# AT32F403A register map
Vendor: Keil; Series: AT32F403A; File version: 1.0
CPU: CM4 r0p1, little endian, no MPU, FPU, 4 interrupt priority bits
Registers are 32-bit, read-write, reset 0x0 unless marked. A register's access mark holds for its fields unless they carry their own. Offsets are from the block's base; [hi:lo] are bit positions; {n}, {i} and the like mark numbered series; 'fields as' and 'values as' point back to an identical list.

## RTC — Real time clock
Base 0x40002800
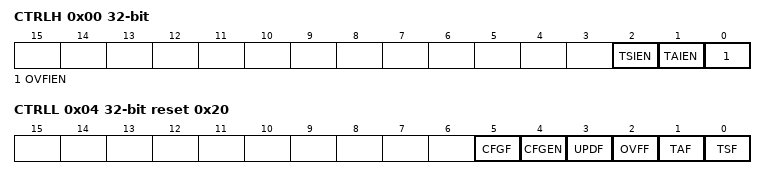
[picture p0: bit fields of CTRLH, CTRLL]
0x00 CTRLH — RTC Control Register High
  [2] TSIEN — Time second interrupt enable
  [1] TAIEN — Time alarm interrupt enable
  [0] OVFIEN — Overflow interrupt enable
0x04 CTRLL reset 0x20 — RTC Control Register Low
  [5] CFGF ro — RTC configuration finish
  [4] CFGEN — RTC configuration enable
  [3] UPDF — RTC update finish
  [2] OVFF — Overflow Flag
  [1] TAF — Time alarm flag
  [0] TSF — Time second flag
0x08 DIVH wo — RTC Divider Register High
  [3:0] DIV — RTC divider high
0x0C DIVL wo reset 0x8000 — RTC Divider Register Low
  [15:0] DIV — RTC divider low
0x10 DIVCNTH — RTC Divider Register High
  [3:0] DIVCNT — RTC divider register high
0x14 DIVCNTL reset 0x8000 — RTC Divider Register Low
  [15:0] DIVCNT — RTC divider register low
0x18 CNTH — RTC Counter Register High
  [15:0] CNT — RTC counter register high
0x1C CNTL — RTC Counter Register Low
  [15:0] CNT — RTC counter register low
0x20 TAH wo reset 0xFFFF — RTC Alarm Register High
  [15:0] TA — Time alarm register high
0x24 TAL wo reset 0xFFFF — Time alarm register low
  [15:0] TA — RTC alarm register low

## BPR — Battery powered register
Base 0x40006C04
0x00 DT{i} (i=1..10; step 0x4) — Battery powered domain data register {i}
  [15:0] DT — BPR data
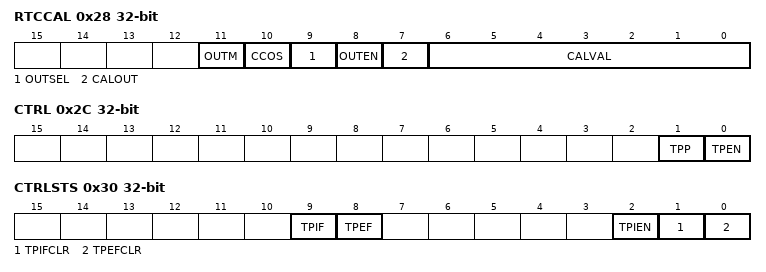
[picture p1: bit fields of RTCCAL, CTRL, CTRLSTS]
0x28 RTCCAL — RTC clock calibration register (BPR_RTCCAL)
  [11] OUTM — Output mode
  [10] CCOS — Calibration clock output selection
  [9] OUTSEL write-1-sets — Output selection
    on read: 0=RTC (RTC alarm event output); 1=Second event output | on write: 1=Second event output
  [8] OUTEN write-1-sets — Output enable
    on read: 0=Disabled (Output is disabled); 1=Enabled (Output is enabled) | on write: 1=Enable (Output enable)
  [7] CALOUT write-1-sets — Calibration Clock Output
    on read: 0=NoOutput (No effect); 1=Output the RTC clock with a frequency divided by 64 on the TAMPER pin | on write: 1=Output the RTC clock with a frequency divided by 64 on the TAMPER pin
  [6:0] CALVAL — Calibration value
0x2C CTRL — BPR control register (BPR_CTRL)
  [1] TPP — TAMPER pin polarity
    0=High (Active high); 1=Low (Active low)
  [0] TPEN — Tamper pin enable
    on read: 0=Disabled (TAMPER pin is disabled); 1=Enabled (TAMPER pin is enabled) | on write: 0=Disable (TAMPER pin disable); 1=Enable (TAMPER pin enable)
0x30 CTRLSTS — BPR control/status register (BPR_CTRLSTS)
  [9] TPIF — Tamper interrupt flag
    on read: 0=NoEvent (No tamper event); 1=Event (A tamper event is detected)
  [8] TPEF — Tamper event flag
    values as TPIF
  [2] TPIEN — Tamper pin interrupt enable
    on read: 0=Disabled (Tamper pin interrupt is disabled); 1=Enabled (Tamper pin interrupt is enabled) | on write: 0=Disable (Tamper pin interrupt disable); 1=Enable (Tamper pin interrupt enable)
  [1] TPIFCLR wo write-1-clears — Tamper interrupt flag clear
    1=Clear (Tamper interrupt flag clear)
  [0] TPEFCLR wo write-1-clears — Tamper event flag clear
    1=Clear the tamper event flag
{0x10+4i} DT{i} (i=11..42) — Battery powered domain data register {i}
  [15:0] DT — BPR data

## WDT — Watchdog
Base 0x40003000
0x00 CMD — Command register
  [15:0] CMD
    0x5555=Unlock write-protected WDT_DIV and WDT_RLD; 0xAAAA=Reload counter; 0xCCCC=Enable WDT. If the hardware watchdog has been enabled, ignore this operation.
0x04 DIV — Division register
  [2:0] DIV — Division divider
    0=LICK divided by 4; 1=LICK divided by 8; 2=LICK divided by 16; 3=LICK divided by 32; 4=LICK divided by 64; 5=LICK divided by 128; 6=LICK divided by 256; 7=div256_2 (LICK divided by 256)
0x08 RLD reset 0xFFF — Reload register
  [11:0] RLD — Reload value
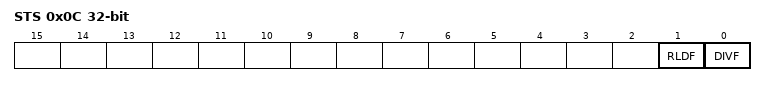
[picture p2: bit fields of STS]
0x0C STS ro — Status register
  [1] RLDF — Reload value update complete flag
    0=Complete (Reload value update complete); 1=InProgress (Reload value update is in process)
  [0] DIVF — Division value update complete flag
    0=Complete (Division value update complete); 1=InProgress (Division value update is in process)
